AUTOSAR XML (schema 4-2-2)
package /Components
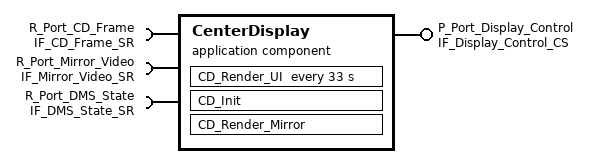
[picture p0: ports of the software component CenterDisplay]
  application sw component type CenterDisplay
    provide port P_Port_Display_Control: provided-interface=IF_Display_Control_CS
    require port R_Port_CD_Frame: required-interface=IF_CD_Frame_SR
    require port R_Port_Mirror_Video: required-interface=IF_Mirror_Video_SR
    require port R_Port_DMS_State: required-interface=IF_DMS_State_SR
    behavior CenterDisplay_InternalBehavior
      data received event CD_UI_Frame_Received: start-on-event=CD_Render_UI
      data received event CD_Mirror_Frame_Received: start-on-event=CD_Render_Mirror
      init event CD_Init_Event: start-on-event=CD_Init
      timing event CD_Update_Tick: start-on-event=CD_Render_UI, period=33
      runnable CD_Init
        parameter access PA_Load_UI_Theme: accessed-parameter=R_Port_CD_Frame.Theme_Id
        parameter access PA_Init_Read_Timestamp: accessed-parameter=R_Port_CD_Frame.Timestamp
      runnable CD_Render_UI
        data-read-access:
          4 x access:
            VA_Read_DMS_Attention: accessed-variable=R_Port_DMS_State.Driver_Attention
            VA_Read_DMS_Drowsiness: accessed-variable=R_Port_DMS_State.Drowsiness_Level
            VA_Read_DMS_EyesOffRoad: accessed-variable=R_Port_DMS_State.Eyes_Off_Road
            VA_Read_DMS_Timestamp: accessed-variable=R_Port_DMS_State.Timestamp
        data-receive-point-by-arguments:
          access VA_Receive_CD_Frame: accessed-variable=R_Port_CD_Frame.CD_Frame
          access VA_Receive_Layer_Composition: accessed-variable=R_Port_CD_Frame.Layer_Composition
          access VA_Receive_CD_Timestamp: accessed-variable=R_Port_CD_Frame.Timestamp
      runnable CD_Render_Mirror
        data-receive-point-by-values:
          access VA_Receive_Mirror_Frame: accessed-variable=R_Port_Mirror_Video.Mirror_Frame
          access VA_Receive_Channel_Id: accessed-variable=R_Port_Mirror_Video.Channel_Id
          access VA_Receive_Mirror_Timestamp: accessed-variable=R_Port_Mirror_Video.Timestamp
